# G32M3101 register map
File version: 1.0
CPU: CM0+ r0p1, little endian, MPU, no FPU, 2 interrupt priority bits
Registers are 32-bit, read-write, reset 0x0 unless marked. A register's access mark holds for its fields unless they carry their own. Offsets are from the block's base; lines under a group give offsets from that group; [hi:lo] are bit positions; {n}, {i} and the like mark numbered series; 'fields as' and 'values as' point back to an identical list; <NAME> marks a mode.

## Memory map
0x40000000 ATMR size 0x400 — Advance timer
0x40001000 GTMR size 0x400 — General purpose timer
0x40002000 BTMR size 0x400 — Base timer
0x40003000 SPI size 0x400 — Serial peripheral interface
0x40004000 UART0 size 0x400 — Universal asynchronous receiver transmitter
0x40005000 UART1 size 0x400 — Universal asynchronous receiver transmitter
0x40006000 COMP size 0x400 — Comparator
0x40007000 WWDT size 0x400 — Window watchdog
0x40008000 IWDT size 0x400 — Independent watchdog
0x40009000 EINT size 0x400 — External interrupt/event controller
0x4000A000 LPTMR size 0x400 — Low-power timer
0x4000B000 ADC size 0x400 — Analog-to-digital converter
0x40020000 DMA size 0x400 — DMA controller
0x40020400 SCU size 0x400 — System configuration controller
0x40020800 FLASH size 0x400 — Flash memory controller
0x40020C00 CRC size 0x400 — Cryptographic processor
0x40021000 DIV size 0x400
0x40021400 GPIOA size 0x400 — General-purpose I/Os
0x40021800 GPIOB size 0x400 — General-purpose I/Os

## Interrupts
0 WWDT — Window Watchdog global interrupt
1 PVD (SCU) — PVD global interrupt
2 LVD (SCU) — PVD global interrupt
3 FLASH — FLASH global interrupt
4 RCM (SCU) — RCM global interrupt
5 EINT0_1 (EINT) — EINT Line 0 to 1 global interrupt
6 EINT2_3 (EINT) — EINT Line 2 to 3 global interrupt
7 EINT4_13 (EINT) — EINT Line 4 to 13 global interrupts
9 DMA_CH0 (DMA) — DMA_CH0 global interrupt
10 DMA_CH1 (DMA) — DMA_CH1 global interrupts
11 DMA_CH2 (DMA) — DMA_CH2 global interrupts
12 ADC — ADC global interrupt
13 ATMR_BRK_UP_TRG_COM (ATMR) — Atimer_BRK_UP_TRG_COM global interrupt
14 ATMR_CC (ATMR) — Atimer_CC global interrupt
15 GTMR — Gtimer interrupt
17 BTMR — Btimer global interrupt
19 LPTMR — LPtimer global interrupt
21 COMP0_1 (COMP) — COMP0 COMP1 global interrupt
25 SPI — SPI global interrupt
27 UART0 — UART0 global interrupt
28 UART1 — UART1 global interrupt

## BTMR — Base timer
Base 0x40002000
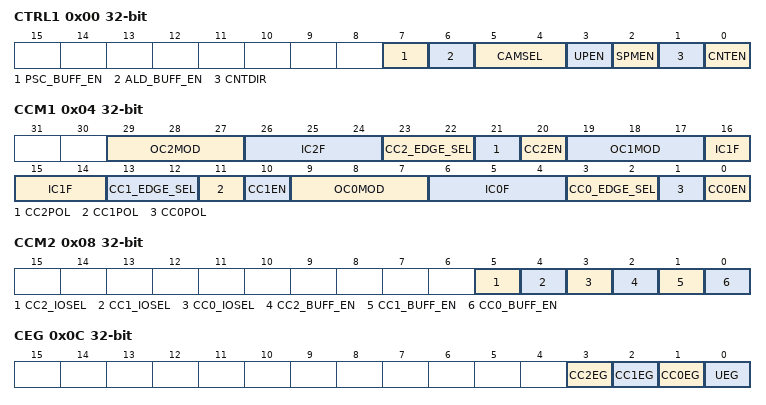
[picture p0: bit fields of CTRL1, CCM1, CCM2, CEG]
0x00 CTRL1 — control register 1
  [7] PSC_BUFF_EN — PSC preload enable
  [6] ALD_BUFF_EN — Auto-reload Preload Enable
  [5:4] CAMSEL — Choose center alignment mode
  [3] UPEN — Update Disable
  [2] SPMEN — Single Pulse Mode Enable
  [1] CNTDIR — Counter Direction
  [0] CNTEN — Timer enable
0x04 CCM1 — capture/compare mode register 1
  [29:27] OC2MOD — Output Compare Channel 2 Mode
  [26:24] IC2F — Input filter coefficients
  [23:22] CC2_EDGE_SEL — Capture Effective Edges
  [21] CC2POL — Capture/Compare Channel2 Output Polarity Configure
  [20] CC2EN — Capture/compare enable
  [19:17] OC1MOD — Output Compare Channel 1 Mode
  [16:14] IC1F — Input filter coefficients
  [13:12] CC1_EDGE_SEL — Capture Effective Edges
  [11] CC1POL — Capture/Compare Channel1 Output Polarity Configure
  [10] CC1EN — Capture/compare enable
  [9:7] OC0MOD — Output Compare Channel 0 Mode
  [6:4] IC0F — Input filter coefficients
  [3:2] CC0_EDGE_SEL — Capture Effective Edges
  [1] CC0POL — Capture/Compare Channel0 Output Polarity Configure
  [0] CC0EN — Capture/compare enable
0x08 CCM2 — capture/compare mode register 2
  [5] CC2_IOSEL
  [4] CC1_IOSEL
  [3] CC0_IOSEL
  [2] CC2_BUFF_EN
  [1] CC1_BUFF_EN
  [0] CC0_BUFF_EN — /
0x0C CEG wo — event generation register
  [3] CC2EG — Capture/compare 2 generation
  [2] CC1EG — Capture/compare 1 generation
  [1] CC0EG — Capture/compare 0 generation
  [0] UEG — Update generation
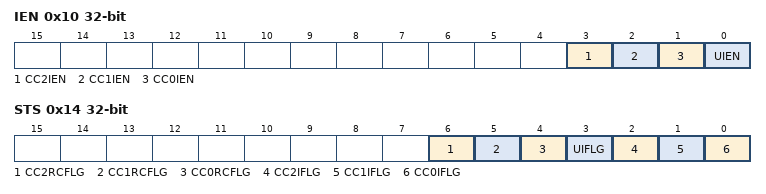
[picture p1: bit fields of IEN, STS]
0x10 IEN — interrupt enable register
  [3] CC2IEN — Capture/Compare 2 interrupt enable
  [2] CC1IEN — Capture/compare 1 interrupt enable
  [1] CC0IEN — Capture/compare 0 interrupt enable
  [0] UIEN — Update interrupt enable
0x14 STS — status register
  [6] CC2RCFLG — Captuer/Compare Channel2 Repetition Capture Flag
  [5] CC1RCFLG — Captuer/Compare Channel1 Repetition Capture Flag
  [4] CC0RCFLG — Captuer/Compare Channel0 Repetition Capture Flag
  [3] UIFLG — Update interrupt flag
  [2] CC2IFLG — Capture/Compare 2 interrupt flag
  [1] CC1IFLG — Capture/compare 1 interrupt flag
  [0] CC0IFLG — Capture/compare 0 interrupt flag
0x18 CNT — counter
  [15:0] CNT — Counter Value
0x1C PSC — prescaler
  [15:0] PSC — Prescaler value
0x20 AUTORLD reset 0xFFFF — auto-reload register
  [15:0] AUTORLD — Auto Reload Value
{0x24+4i} CC{i} (i=0..2) — capture/compare register {i}
  [15:0] CC{i} — Capture/Compare {i} value
